# CC3200 register map
Vendor: Texas Instruments; Series: SimpleLink; File version: 1.0
CPU: CM4 r0p1, little endian, MPU, no FPU, 3 interrupt priority bits
Registers are 32-bit, read-write, reset 0x0 unless marked. A register's access mark holds for its fields unless they carry their own. Offsets are from the block's base; [hi:lo] are bit positions; {n}, {i} and the like mark numbered series.

## STACK_DIE_CTRL
Base 0x400F5000
0x00 STK_UP_RESET — STACK_DIE_CTRL_STK_UP_RESET
  [0] UP_RESET
0x04 SR_MASTER_PRIORITY — STACK_DIE_CTRL_SR_MASTER_PRIORITY
  [1:0] PRIORITY_M
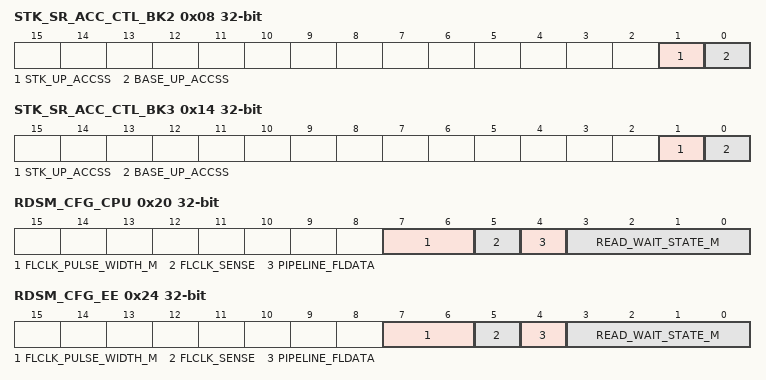
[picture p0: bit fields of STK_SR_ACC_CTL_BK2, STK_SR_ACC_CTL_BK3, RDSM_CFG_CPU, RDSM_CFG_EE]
0x08 STK_SR_ACC_CTL_BK2 — STACK_DIE_CTRL_STK_SR_ACC_CTL_BK2
  [1] STK_UP_ACCSS — STACK_DIE_CTRL_STK_SR_ACC_CTL_BK2
  [0] BASE_UP_ACCSS — STACK_DIE_CTRL_STK_SR_ACC_CTL_BK2
0x0C BASE_UP_ACC_REQ_BK2 — STACK_DIE_CTRL_BASE_UP_ACC_REQ_BK2
  [0] ACCSS_REQ
0x10 STK_UP_ACC_REQ_BK2 — STACK_DIE_CTRL_STK_UP_ACC_REQ_BK2
  [0] ACCSS_REQ
0x14 STK_SR_ACC_CTL_BK3 — STACK_DIE_CTRL_STK_SR_ACC_CTL_BK3
  [1] STK_UP_ACCSS — STACK_DIE_CTRL_STK_SR_ACC_CTL_BK3
  [0] BASE_UP_ACCSS — STACK_DIE_CTRL_STK_SR_ACC_CTL_BK3
0x18 BASE_UP_ACC_REQ_BK3 — STACK_DIE_CTRL_BASE_UP_ACC_REQ_BK3
  [0] ACCSS_REQ
0x1C STK_UP_ACC_REQ_BK3 — STACK_DIE_CTRL_STK_UP_ACC_REQ_BK3
  [0] ACCSS_REQ
0x20 RDSM_CFG_CPU — STACK_DIE_CTRL_RDSM_CFG_CPU
  [7:6] FLCLK_PULSE_WIDTH_M — STACK_DIE_CTRL_RDSM_CFG_CPU
  [5] FLCLK_SENSE — STACK_DIE_CTRL_RDSM_CFG_CPU
  [4] PIPELINE_FLDATA — STACK_DIE_CTRL_RDSM_CFG_CPU
  [3:0] READ_WAIT_STATE_M — STACK_DIE_CTRL_RDSM_CFG_CPU
0x24 RDSM_CFG_EE — STACK_DIE_CTRL_RDSM_CFG_EE
  [7:6] FLCLK_PULSE_WIDTH_M — STACK_DIE_CTRL_RDSM_CFG_EE
  [5] FLCLK_SENSE — STACK_DIE_CTRL_RDSM_CFG_EE
  [4] PIPELINE_FLDATA — STACK_DIE_CTRL_RDSM_CFG_EE
  [3:0] READ_WAIT_STATE_M — STACK_DIE_CTRL_RDSM_CFG_EE
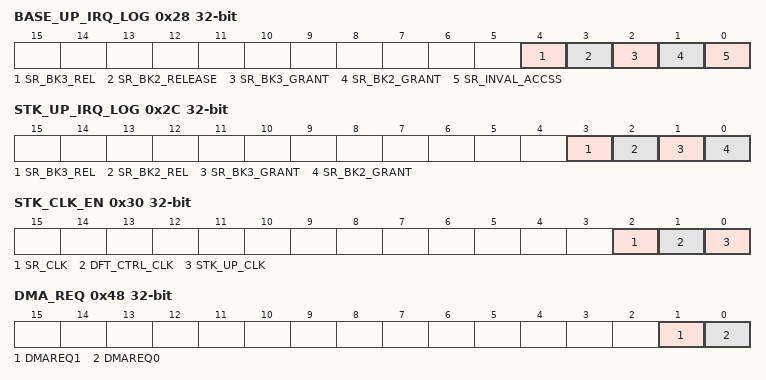
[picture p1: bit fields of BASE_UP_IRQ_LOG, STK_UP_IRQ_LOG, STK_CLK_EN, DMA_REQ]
0x28 BASE_UP_IRQ_LOG — STACK_DIE_CTRL_BASE_UP_IRQ_LOG
  [4] SR_BK3_REL — STACK_DIE_CTRL_BASE_UP_IRQ_LOG
  [3] SR_BK2_RELEASE — STACK_DIE_CTRL_BASE_UP_IRQ_LOG
  [2] SR_BK3_GRANT — STACK_DIE_CTRL_BASE_UP_IRQ_LOG
  [1] SR_BK2_GRANT — STACK_DIE_CTRL_BASE_UP_IRQ_LOG
  [0] SR_INVAL_ACCSS — STACK_DIE_CTRL_BASE_UP_IRQ_LOG
0x2C STK_UP_IRQ_LOG — STACK_DIE_CTRL_STK_UP_IRQ_LOG
  [3] SR_BK3_REL — STACK_DIE_CTRL_STK_UP_IRQ_LOG
  [2] SR_BK2_REL — STACK_DIE_CTRL_STK_UP_IRQ_LOG
  [1] SR_BK3_GRANT — STACK_DIE_CTRL_STK_UP_IRQ_LOG
  [0] SR_BK2_GRANT — STACK_DIE_CTRL_STK_UP_IRQ_LOG
0x30 STK_CLK_EN — STACK_DIE_CTRL_STK_CLK_EN
  [2] SR_CLK — STACK_DIE_CTRL_STK_CLK_EN
  [1] DFT_CTRL_CLK — STACK_DIE_CTRL_STK_CLK_EN
  [0] STK_UP_CLK — STACK_DIE_CTRL_STK_CLK_EN
0x34 SPIN_LOCK_MODE — STACK_DIE_CTRL_SPIN_LOCK_MODE
  [0] MODE
0x38 BUS_FAULT_ADDR — STACK_DIE_CTRL_BUS_FAULT_ADDR
  [31:0] ADDRESS_M
0x3C BUS_FAULT_CLR — STACK_DIE_CTRL_BUS_FAULT_CLR
  [0] CLEAR
0x40 RESET_CAUSE — STACK_DIE_CTRL_RESET_CAUSE
  [31:0] RST_CAUSE_M
0x44 WDOG_TIMER_EVENT — STACK_DIE_CTRL_WDOG_TIMER_EVENT
  [31:0] WDOG_TMR_EVNT_M
0x48 DMA_REQ — STACK_DIE_CTRL_DMA_REQ
  [1] DMAREQ1 — STACK_DIE_CTRL_DMA_REQ
  [0] DMAREQ0 — STACK_DIE_CTRL_DMA_REQ
0x4C SRAM_JUMP_OFFSET_ADDR — STACK_DIE_CTRL_SRAM_JUMP_OFFSET_ADDR
  [31:0] ADDR_M
0x50 SW_REG1 — STACK_DIE_CTRL_SW_REG1
  [31:0] NEWBITFIELD1_M
0x54 SW_REG2 — STACK_DIE_CTRL_SW_REG2
  [31:0] NEWBITFIELD1_M
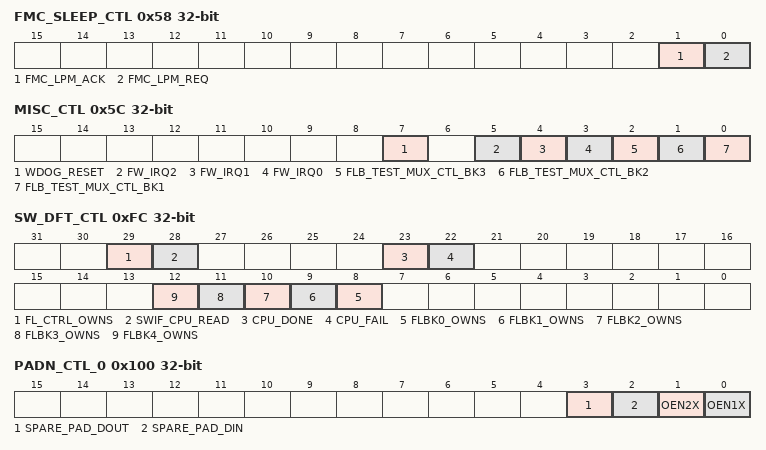
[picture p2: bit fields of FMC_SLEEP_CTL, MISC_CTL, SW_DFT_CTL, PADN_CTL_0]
0x58 FMC_SLEEP_CTL — STACK_DIE_CTRL_FMC_SLEEP_CTL
  [1] FMC_LPM_ACK — STACK_DIE_CTRL_FMC_SLEEP_CTL
  [0] FMC_LPM_REQ — STACK_DIE_CTRL_FMC_SLEEP_CTL
0x5C MISC_CTL — STACK_DIE_CTRL_MISC_CTL
  [7] WDOG_RESET — STACK_DIE_CTRL_MISC_CTL
  [5] FW_IRQ2 — STACK_DIE_CTRL_MISC_CTL
  [4] FW_IRQ1 — STACK_DIE_CTRL_MISC_CTL
  [3] FW_IRQ0 — STACK_DIE_CTRL_MISC_CTL
  [2] FLB_TEST_MUX_CTL_BK3 — STACK_DIE_CTRL_MISC_CTL
  [1] FLB_TEST_MUX_CTL_BK2 — STACK_DIE_CTRL_MISC_CTL
  [0] FLB_TEST_MUX_CTL_BK1 — STACK_DIE_CTRL_MISC_CTL
0xFC SW_DFT_CTL — STACK_DIE_CTRL_SW_DFT_CTL
  [29] FL_CTRL_OWNS — STACK_DIE_CTRL_SW_DFT_CTL
  [28] SWIF_CPU_READ — STACK_DIE_CTRL_SW_DFT_CTL
  [23] CPU_DONE — STACK_DIE_CTRL_SW_DFT_CTL
  [22] CPU_FAIL — STACK_DIE_CTRL_SW_DFT_CTL
  [n+8] FLBK{n}_OWNS (n=0..4) — STACK_DIE_CTRL_SW_DFT_CTL
0x100 PADN_CTL_0 — STACK_DIE_CTRL_PADN_CTL_0
  [3] SPARE_PAD_DOUT — STACK_DIE_CTRL_PADN_CTL_0
  [2] SPARE_PAD_DIN — STACK_DIE_CTRL_PADN_CTL_0
  [1] OEN2X — STACK_DIE_CTRL_PADN_CTL_0
  [0] OEN1X — STACK_DIE_CTRL_PADN_CTL_0
